# DMASS_DTHE_DMASS_DTHE_DTHE_DTHE_CFG_TRNG76D_WRAP_VBUSP_EIP_76D_8_BCDF_EIP76_4080A000h register map
Vendor: Texas Instruments
Peripheral module from a debugger description file (folder am62L).
Registers are 32-bit, read-only, reset 0x0 unless marked. A register's access mark holds for its fields unless they carry their own. Offsets are as the file gives them; lines under a group give offsets from that group; [hi:lo] are bit positions; {n}, {i} and the like mark numbered series; 'fields as' and 'values as' point back to an identical list; <NAME> marks a mode.

## DMASS_DTHE_DTHE_DTHE_CFG_TRNG76D_WRAP_VBUSP_EIP_76D_8_BCDF_EIP76
0x00 DMASS_DTHE_DTHE_DTHE_CFG_TRNG76D_WRAP_VBUSP_EIP_76D_8_BCDF_EIP76_TRNG_INPUT_0 wo — Input for SP800-90A AES DRBG test
  [31:0] TRNG_INPUT_0 — Write only, least significant word of 128-bit word of test data for [SP 800-90A] AES-256 DRBG testing; may be written when test_ready bit in the TRNG_STATUS register has value 1.
0x00 DMASS_DTHE_DTHE_DTHE_CFG_TRNG76D_WRAP_VBUSP_EIP_76D_8_BCDF_EIP76_TRNG_OUTPUT_0 — Main data output
  [31:0] TRNG_OUTPUT_0 — Read only, least significant word of 128-bit word of random data, only valid when the ready bit in the TRNG_STATUS register has value 1.
0x04 DMASS_DTHE_DTHE_DTHE_CFG_TRNG76D_WRAP_VBUSP_EIP_76D_8_BCDF_EIP76_TRNG_INPUT_1 wo — Input for SP800-90A AES DRBG test
  [31:0] TRNG_INPUT_1 — Write only, second word of 128-bit word of test data for [SP 800-90A] AES-256 DRBG testing; may be written when test_ready bit in the TRNG_STATUS register has value 1.
0x04 DMASS_DTHE_DTHE_DTHE_CFG_TRNG76D_WRAP_VBUSP_EIP_76D_8_BCDF_EIP76_TRNG_OUTPUT_1 — Main data output
  [31:0] TRNG_OUTPUT_1 — Read only, second word of 128-bit word of random data, only valid when the ready bit in the TRNG_STATUS register has value 1.
0x08 DMASS_DTHE_DTHE_DTHE_CFG_TRNG76D_WRAP_VBUSP_EIP_76D_8_BCDF_EIP76_TRNG_INPUT_2 wo — Input for SP800-90A AES DRBG test
  [31:0] TRNG_INPUT_2 — Write only, third word of 128-bit word of test data for [SP 800-90A] AES-256 DRBG testing; may be written when test_ready bit in the TRNG_STATUS register has value 1.
0x08 DMASS_DTHE_DTHE_DTHE_CFG_TRNG76D_WRAP_VBUSP_EIP_76D_8_BCDF_EIP76_TRNG_OUTPUT_2 — Main data output
  [31:0] TRNG_OUTPUT_2 — Read only, third word of 128-bit word of random data, only valid when the ready bit in the TRNG_STATUS register has value 1.
0x0C DMASS_DTHE_DTHE_DTHE_CFG_TRNG76D_WRAP_VBUSP_EIP_76D_8_BCDF_EIP76_TRNG_INPUT_3 wo — Input for SP800-90A AES DRBG test
  [31:0] TRNG_INPUT_3 — Write only, most significant word of 128-bit word of test data for [SP 800-90A] AES-256 DRBG testing; may be written when test_ready bit in the TRNG_STATUS register has value 1.
0x0C DMASS_DTHE_DTHE_DTHE_CFG_TRNG76D_WRAP_VBUSP_EIP_76D_8_BCDF_EIP76_TRNG_OUTPUT_3 — Main data output
  [31:0] TRNG_OUTPUT_3 — Read only, most significant word of 128-bit word of random data, only valid when the ready bit in the TRNG_STATUS register has value 1.
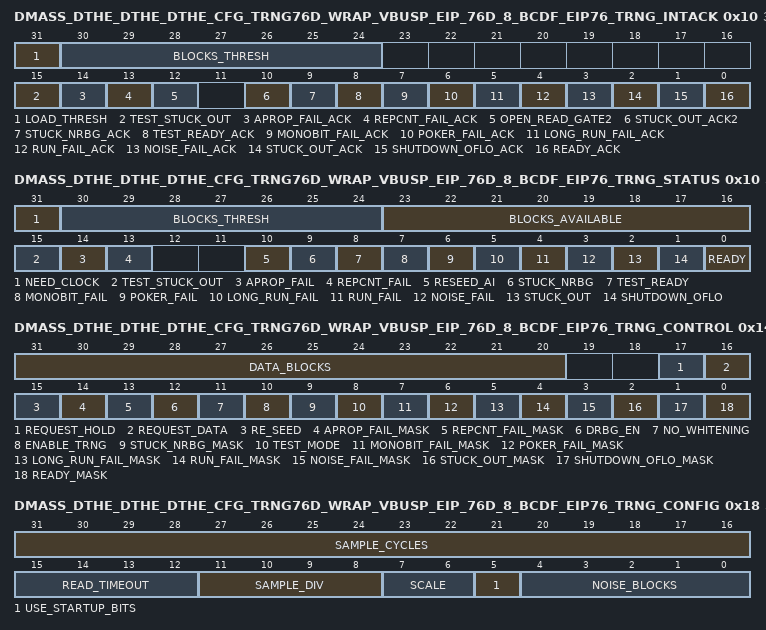
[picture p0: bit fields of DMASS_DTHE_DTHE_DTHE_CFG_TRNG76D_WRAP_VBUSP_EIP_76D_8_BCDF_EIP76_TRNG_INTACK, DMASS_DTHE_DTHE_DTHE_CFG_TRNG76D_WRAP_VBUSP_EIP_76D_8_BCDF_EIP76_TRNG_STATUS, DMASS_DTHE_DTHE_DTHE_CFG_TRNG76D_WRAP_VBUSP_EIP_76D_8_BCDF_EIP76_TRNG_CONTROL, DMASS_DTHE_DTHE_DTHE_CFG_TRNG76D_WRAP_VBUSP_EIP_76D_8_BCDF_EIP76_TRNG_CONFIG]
0x10 DMASS_DTHE_DTHE_DTHE_CFG_TRNG76D_WRAP_VBUSP_EIP_76D_8_BCDF_EIP76_TRNG_INTACK wo — This register is written to acknowledge interrupts indicated in bits [14:0] of the TRNG_STATUS register. Writing a 1 to any of the bits [7:2] here has side effects in resetting various parts of the EIP-76 core logic. This can also be used even if no interrupts are actually active.
  [31] LOAD_THRESH — Write a 1 to load the blocks_thresh field with a new value.
  [30:24] BLOCKS_THRESH — The value written here with load_thresh a 1 determines the filling level of the buffer RAM that must be reached to generate a data available indication the ready bit in the TRNG_STATUS register
  [15] TEST_STUCK_OUT — Write a 1 to enable the stuck_out detection logic testing which prevents updating the data fed to the output buffer module. Can only be modified when also Writing a 1 to stuck_out_ack or stuck_out_ack2 here and can only be set to 1 when test_mode in the TRNG_CONTROL register is a 1.
  [14] APROP_FAIL_ACK — Write a 1 to clear the aprop_fail bit in the TRNG_STATUS register and also clear the aprop_64_fail and aprop_512_fail bits, aprop_64_counter and aprop_512_counter in the TRNG_SPB_TESTS register
  [13] REPCNT_FAIL_ACK — Write a 1 to clear the repcnt_fail bit in the TRNG_STATUS register.
  [12] OPEN_READ_GATE2 — In secure Reading mode, write a 1b here to enable Reading of EIP-76 data from the TRNG_OUTPUT_... registers
  [10] STUCK_OUT_ACK2 — Write a 1 to clear the stuck_out bit in the TRNG_STATUS register.
  [9] STUCK_NRBG_ACK — Write a 1 to clear the stuck_nrbg bit in the TRNG_STATUS register.
  [8] TEST_READY_ACK — Write a 1 to clear the test_ready bit in the TRNG_STATUS register.
  [7] MONOBIT_FAIL_ACK — Write a 1 to clear the monobit_fail bit in the TRNG_STATUS register.
  [6] POKER_FAIL_ACK — Write a 1 to clear the poker_fail bit in the TRNG_STATUS register.
  [5] LONG_RUN_FAIL_ACK — Write a 1 to clear the long_run_fail bit in the TRNG_STATUS register.
  [4] RUN_FAIL_ACK — Write a 1 to clear the run_fail bit in the TRNG_STATUS register.
  [3] NOISE_FAIL_ACK — Write a 1 to clear the noise_fail bit in the TRNG_STATUS register.
  [2] STUCK_OUT_ACK — Write a 1 to clear the stuck_out bit in the TRNG_STATUS register.
  [1] SHUTDOWN_OFLO_ACK — Write a 1 to clear the shutdown_oflo bit in the TRNG_STATUS register.
  [0] READY_ACK — Write a 1 to clear the ready bit in the TRNG_STATUS register.
0x10 DMASS_DTHE_DTHE_DTHE_CFG_TRNG76D_WRAP_VBUSP_EIP_76D_8_BCDF_EIP76_TRNG_INTACK_secure_mode wo — When secure reading mode is enabled, bits [15:0] of this register must be written with zeroes to enable reading of EIP-76 data from the TRNG_OUTPUT_... registers. This also starts the (configurable) timeout counter that will automatically acknowledge the EIP-76 data (and disable reading) if ready_ack is not written with a 1 here within that timeout period.
  [14:0] READY — In secure Reading mode, write an all zeroes value to bits [15:0] to enable Reading of EIP-76 data from the TRNG_OUTPUT_... registers
0x10 DMASS_DTHE_DTHE_DTHE_CFG_TRNG76D_WRAP_VBUSP_EIP_76D_8_BCDF_EIP76_TRNG_STATUS reset 0x400 — The stuck_out and noise_fail bits in this register are considered to signal fatal errors. The shutdown_oflo bit is considered to signal a fatal error when the shutdown_fatal bit in the TRNG_ALARMCNT register is set to 1. If the corresponding ..._mask bits TRNG_CONTROL register are 1 to enable generating an interrupt via the irq output, occurrence of a fatal error disables the TRNG by resetting the enable_trng bit in the TRNG_CONTROL register, zeroizes the random values buffer and forces the ready bit in this register to 0.
  [31] NEED_CLOCK — indicates that the TRNG is busy generating entropy or is in one of its test modes - the module clock may not be turned off. This bit is a direct mirror of the need_clock output signal of the module.
  [30:24] BLOCKS_THRESH — The threshold value for the blocks_available field to indicate ready here. The value is written via bits [30:24] of the TRNG_INTACK register. The number of blocks available in the RAM buffer must be equal to or greater than the value in this field
  [23:16] BLOCKS_AVAILABLE — This field indicates the number of 128 bits blocks of random data that are available in the random data RAM buffer. If this value is non-zero, the output registers will be re-filled from the random data RAM buffer immediately after acknowledging the ready interrupt
  [15] TEST_STUCK_OUT — indication that stuck_out functionality testing is enabled
  [14] APROP_FAIL — 1=the SP 800-90B Adaptive Proportion test logic monitoring the data shifted into the main shift register detected too many 8-bit Noise Source output samples matching the first sample taken in the test window.
  [13] REPCNT_FAIL — 1=the SP 800-90B Repetition Count test logic monitoring the data shifted into the main shift register detected a number of consecutive identical 8-bit Noise Source output samples that matched the programmed cutoff value.
  [10] RESEED_AI — For the EIP-76d configurations with BC_DF functionality, this bit indicates when the TRNG_PS_AI_ registers must be written for an Instantiate or Reseed operation. Writing the highest Byte of the TRNG_PS_AI_11 register then clears this bit. This bit also indicates when the DRBG has finished updating its internal Key and V values after generating random data; no specific action is required at that time.
  [9] STUCK_NRBG — NRBG stuck error; this happens when two identical values were extracted from the main shift register
  [8] TEST_READY — Multi-purpose bit. Please refer to eip76d HW Reference Manual for details
  [7] MONOBIT_FAIL — 1=monobit test logic monitoring data shifted into the main shift register detected an out-of-bounds number of 1s after checking 20,000 bits.
  [6] POKER_FAIL — 1=the AIS-31 poker test logic monitoring data shifted into the main shift register detected an out-of-bounds value in at least one of the 16 poker_count_X counters or an out of bounds sum of squares value after checking 20,000 bits.
  [5] LONG_RUN_FAIL — 1=the AIS-31 run test logic monitoring data shifted into the main shift register detected a sequence of 34 identical bits.
  [4] RUN_FAIL — 1=the AIS-31 run test logic monitoring data shifted into the main shift register detected an out-of-bounds value for at least one of the run_X_count_... counters after checking 20,000 bits.
  [3] NOISE_FAIL — 1=the AIS-31 run test logic monitoring data shifted into the main shift register detected a sequence of 48 identical bits, which is considered a Noise Source failure as proposed in section E.5 of the AIS-31 standard.
  [2] STUCK_OUT — 1=logic around the output data registers4 detected that the EIP-76 generates the same value twice in a row. The word size for this comparison is 128 bits.
  [1] SHUTDOWN_OFLO — 1=the number of FROs shut down after a second error event i.e. the number of 1 bits in the TRNG_ALARMSTOP register has exceeded the threshold set by shutdown_threshold in the TRNG_ALARMCNT register.
  [0] READY — 1=data is available in the TRNG_OUTPUT_0...3 registers. Acknowledging this state by Writing a 1 to bit [0] of the TRNG_INTACK register clears this bit to 0. If a new number is already available in the random data buffer, that number is directly moved into the result register. In this case the ready status bit is asserted again, after at most six module clock cycles.
0x14 DMASS_DTHE_DTHE_DTHE_CFG_TRNG76D_WRAP_VBUSP_EIP_76D_8_BCDF_EIP76_TRNG_CONTROL access per field — This register must be written to start accumulating entropy before random numbers can be generated.
  [31:20] DATA_BLOCKS rw — This field indicates the number of 128 bit data blocks that must be generated by the [SP 800-90A] AES-256 DRBG in a single Generate_function. It is loaded in a write to this register where the request_data bit is 1 (and the re_seed bit is 0) and then counts down to zero by one for each block that is generated.
  [17] REQUEST_HOLD rw — Value 1 in this bit indicates that bits [31:24] of the data_blocks field must be loaded with a separate Byte write
  [16] REQUEST_DATA wo — Write-only, Writing a 1 indicates that the data_blocks field contains the number of 128 bit data blocks that the [SP 800-90A] AES-256 DRBG should generate in a single Generate_function
  [15] RE_SEED rw — Set-only, Writing a 1 starts a Reseed operation. Writing a 0 has no effect.
  [14] APROP_FAIL_MASK rw — 1=allow the corresponding bit in the TRNG_STATUS register to activate the active high irq output
  [13] REPCNT_FAIL_MASK rw — 1=allow the corresponding bit in the TRNG_STATUS register to activate the active high irq output
  [12] DRBG_EN rw — Enable the [SP 800-90A] AES-256 DRBG. If this bit is reset to 0, the DRBG is forced back into the idle state immediately.
  [11] NO_WHITENING rw — The default value of 0 means that toggle-flop whitening of the noise source is enabled. Set this bit to 1 to disable the toggle flip-flop based whitening of the noise source
  [10] ENABLE_TRNG rw — Setting this bit to 1 starts the EIP-76, gathering entropy from the FROs. Resetting this bit to 0 forces all NRBG logic back into the idle state immediately. For the [SP 800-90A] DRBG option, starting the EIP-76 with the drbg_en bit value 1 performs a CTR_DRBG Instantiate operation with Personalization String as written to the TRNG_PS_AI_... registers at that time.
  [9] STUCK_NRBG_MASK rw — 1=allow the corresponding bit in the TRNG_STATUS register to activate the active high irq output
  [8] TEST_MODE rw — Enables access to (amongst others) the TRNG_COUNT and TRNG_RAW_L/H registers (the latter are cleared before enabling access) and keep need_clock output active high for testing purposes. This bit must be set to 1 before various test modes in the TRNG_TEST register can be enabled
  [7] MONOBIT_FAIL_MASK rw — 1=allow the corresponding bit in the TRNG_STATUS register to activate the active high irq output
  [6] POKER_FAIL_MASK rw — 1=allow the corresponding bit in the TRNG_STATUS register to activate the active high irq output
  [5] LONG_RUN_FAIL_MASK rw — 1=allow the corresponding bit in the TRNG_STATUS register to activate the active high irq output
  [4] RUN_FAIL_MASK rw — 1=allow the corresponding bit in the TRNG_STATUS register to activate the active high irq output
  [3] NOISE_FAIL_MASK rw — 1=allow the corresponding bit in the TRNG_STATUS register to activate the active high irq output
  [2] STUCK_OUT_MASK rw — 1=allow the corresponding bit in the TRNG_STATUS register to activate the active high irq output
  [1] SHUTDOWN_OFLO_MASK rw — 1=allow the corresponding bit in the TRNG_STATUS register to activate the active high irq output
  [0] READY_MASK rw — 1=allow the corresponding bit in the TRNG_STATUS register to activate the active high irq output
0x18 DMASS_DTHE_DTHE_DTHE_CFG_TRNG76D_WRAP_VBUSP_EIP_76D_8_BCDF_EIP76_TRNG_CONFIG rw — TRNG Configuration register
  [31:16] SAMPLE_CYCLES — This field, together with the scale field, defines the number of clock cycles before shifting the main shift register and thereby freezing the noise sample. This value must be such that there is at least one bit of entropy (in total) in each 8 bits that are shifted. Please refer to eip76d HW Reference Manual for details
  [15:12] READ_TIMEOUT — This field controls the secure Reading mode. Please refer to eip76d HW Reference Manual for details
  [11:8] SAMPLE_DIV — This field directly controls the number of clk input cycles between samples taken from the FROs. Please refer to eip76d HW Reference Manual for details
  [7:6] SCALE — Set the scale factor for the sample_cycles value. Please refer to eip76d HW Reference Manual for details
  [5] USE_STARTUP_BITS — Do not discard the first 512 bits of raw data. This reduces the start-up time, but may more frequently cause start-up health test failures.
  [4:0] NOISE_BLOCKS — This field sets the number of 512-bit blocks of raw Noise Source output data that must be processed by either the Conditioning Function or the SP 800-90 DRBG BC_DF functionality
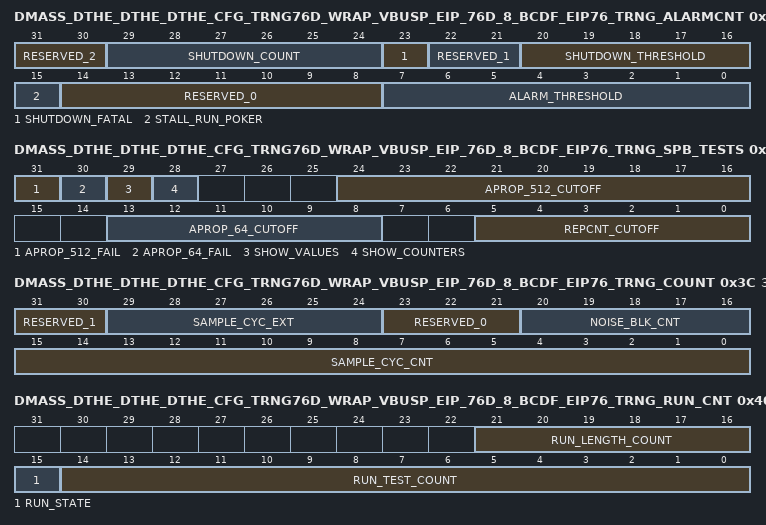
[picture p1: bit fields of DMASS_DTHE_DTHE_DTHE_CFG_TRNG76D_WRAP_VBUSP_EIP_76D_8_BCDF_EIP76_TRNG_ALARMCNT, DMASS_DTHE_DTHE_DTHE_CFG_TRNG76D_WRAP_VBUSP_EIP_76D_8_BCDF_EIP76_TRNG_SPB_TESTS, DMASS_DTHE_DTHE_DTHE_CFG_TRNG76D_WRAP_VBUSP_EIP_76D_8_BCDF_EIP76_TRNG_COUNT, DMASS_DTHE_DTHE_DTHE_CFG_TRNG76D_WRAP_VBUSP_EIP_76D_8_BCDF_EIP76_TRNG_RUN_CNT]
0x1C DMASS_DTHE_DTHE_DTHE_CFG_TRNG76D_WRAP_VBUSP_EIP_76D_8_BCDF_EIP76_TRNG_ALARMCNT access per field reset 0xFF — This register, together with the TRNG_ALARMMASK and TRNG_ALARMSTOP registers, can be used by the Host to determine if the FRO/sample cycle locking is a problem.
  [31:30] RESERVED_2 ro — Bits should be written with a 0 and should be ignored on a read.
  [29:24] SHUTDOWN_COUNT ro — Read-only, indicates the number of 1 bits in the TRNG_ALARMSTOP register. The actual maximum value equals the number of FROs.
  [23] SHUTDOWN_FATAL rw — Threshold setting for generating the shutdown_oflo interrupt, which is activated when the shutdown_count value in this register exceeds the threshold value set here.
  [22:21] RESERVED_1 ro — Bits should be written with a 0 and should be ignored on a read.
  [20:16] SHUTDOWN_THRESHOLD rw — Threshold setting for generating the shutdown_oflo interrupt, which is activated when the shutdown_count value in this register exceeds the threshold value set here.
  [15] STALL_RUN_POKER rw — 1 = Stall the monobit test, run test and poker test circuits when either the monobit_fail, run_fail or poker_fail bits in the TRNG_STATUS register are set to 1 - this allows inspecting the state of the result counters (which would otherwise be reset immediately for the next 20,000 bits block to test)
  [14:8] RESERVED_0 ro — Bits should be written with a 0 and should be ignored on a read.
  [7:0] ALARM_THRESHOLD rw — Alarm detection threshold for the repeating pattern detectors on each FRO. A FRO alarm event is declared when a repeating pattern (of up to four samples length) is detected continuously for the number of samples defined by this field's value. Reset value 255 (decimal) should keep the number of alarm events to a manageable level.
0x20 DMASS_DTHE_DTHE_DTHE_CFG_TRNG76D_WRAP_VBUSP_EIP_76D_8_BCDF_EIP76_TRNG_FROENABLE rw reset 0xFF — This register can be used by the Host to enable and disable FROs individually. Only enabled FROs contribute to entropy generation, but require power to do so. Disabled FROs cannot generate alarm events.
  [7:0] TRNG_FROENABLE — Enable bits for the individual FROs. A 1 in bit [n] enables FRO n. The default state is all ones to enable all FROs after power-up. Note that they are not actually started up before the enable_trng bit in the TRNG_CONTROL register is set to 1. A bit is automatically forced to 0 here (and cannot be written to 1) when the corresponding bit in the TRNG_ALARMSTOP register has value 1.
0x24 DMASS_DTHE_DTHE_DTHE_CFG_TRNG76D_WRAP_VBUSP_EIP_76D_8_BCDF_EIP76_TRNG_FRODETUNE rw — This register can be used by the Host to change the frequencies of individual FROs. This may be used in an effort to reduce the number of alarm events generated by a specific FRO.
  [7:0] TRNG_FRODETUNE — De-tune bits for the individual FROs. A 1 in bit [n] lets FRO n run approximately 5% faster. The value of one of these bits may only be changed while the corresponding FRO is turned off (by temporarily Writing a 0 in the corresponding bit of the TRNG_FROENABLE register).
0x28 DMASS_DTHE_DTHE_DTHE_CFG_TRNG76D_WRAP_VBUSP_EIP_76D_8_BCDF_EIP76_TRNG_ALARMMASK rw — This register can be used by the Host to determine which of the individual FROs generated an alarm event.
  [7:0] TRNG_ALARMMASK — Logging bits for the alarm events of individual FROs. A 1 in bit [n] indicates FRO n experienced an alarm event.
0x2C DMASS_DTHE_DTHE_DTHE_CFG_TRNG76D_WRAP_VBUSP_EIP_76D_8_BCDF_EIP76_TRNG_ALARMSTOP rw — This register can be used by the Host to determine which of the individual FROs generated more than one alarm event in quick succession
  [7:0] TRNG_ALARMSTOP — Logging bits for the alarm events of individual FROs. A 1 in bit [n] indicates FRO n experienced more than one alarm event in quick succession and has been turned off. A 1 in this field forces the corresponding bit in the TRNG_FROENABLE register to 0.
0x30 DMASS_DTHE_DTHE_DTHE_CFG_TRNG76D_WRAP_VBUSP_EIP_76D_8_BCDF_EIP76_TRNG_RAW_L rw — These registers are used to access the main shift register (or its read buffer register) while the test_mode bit in TRNG_CONTROL is set to 1 and either the test_noise or test_known_noise bits in the TRNG_TEST register are set to 1. For security reasons, the main shift register and its buffer register are zeroed when the test_mode bit in TRNG_CONTROL is written from 0 to 1
  [31:0] TRNG_RAW_L — When test_mode in TRNG_CONTROL = 1, test_noise in TRNG_TEST = 1 and test_shiftreg in TRNG_TEST = 0: read-only access to the main shift registers read buffer register bits [31:0]. When test_mode in TRNG_CONTROL = 1, test_noise in TRNG_TEST = 1 and test_shiftreg in TRNG_TEST = 1: read-only access to main shift register bits [31:0]. When test_mode in TRNG_CONTROL = 1 and test_known_noise in TRNG_TEST = 1: write-only access to main shift register bits [31:0].
0x34 DMASS_DTHE_DTHE_DTHE_CFG_TRNG76D_WRAP_VBUSP_EIP_76D_8_BCDF_EIP76_TRNG_RAW_H rw — These registers are used to access the main shift register (or its read buffer register) while the test_mode bit in TRNG_CONTROL is set to 1 and either the test_noise or test_known_noise bits in the TRNG_TEST register are set to 1. For security reasons, the main shift register and its buffer register are zeroed when the test_mode bit in TRNG_CONTROL is written from 0 to 1
  [31:0] TRNG_RAW_H — When test_mode in TRNG_CONTROL = 1, test_noise in TRNG_TEST = 1 and test_shiftreg in TRNG_TEST = 0: read-only access to the main shift registers read buffer register bits [63:32]. When test_mode in TRNG_CONTROL = 1, test_noise in TRNG_TEST = 1 and test_shiftreg in TRNG_TEST = 1: read-only access to main shift register bits [63:32]. When test_mode in TRNG_CONTROL = 1 and test_known_noise in TRNG_TEST = 1: write-only access to main shift register bits [63:32].
0x38 DMASS_DTHE_DTHE_DTHE_CFG_TRNG76D_WRAP_VBUSP_EIP_76D_8_BCDF_EIP76_TRNG_SPB_TESTS rw reset 0x145381F — Allows setting the cutoff values for the Repetition Count and Adaptive Proportion tests required by that standard. The Adaptive Proportion test is run with window sizes of 512 and 64 Noise Source samples in parallel. All these tests use 8-bit Noise Source samples. In test_spb mode, this register allows monitoring the counters and compare values.
  [31] APROP_512_FAIL — Bit indicating that the aprop_512_counter was equal to the aprop_512_cutoff setting. The state of this bit is OR-ed with the aprop_64_fail bit into the aprop_fail bit in the TRNG_STATUS register and cleared to 0 when Writing a 1 to the aprop_fail_ack bit of the TRNG_INTACK register. While normal
  [30] APROP_64_FAIL — Bit indicating that the aprop_64_counter was equal to the aprop_64_cutoff setting. The state of this bit is OR-ed with the aprop_512_fail bit into the aprop_fail bit in the TRNG_STATUS register and cleared to 0 when Writing a 1 to the aprop_fail_ack bit of the TRNG_INTACK register. While normally read-only, this bit can be written when test_spb in TRNG_TEST is 1.
  [29] SHOW_VALUES — Bit controlling what is actually accessible in this register; can only be set to 1 when test_spb in TRNG_TEST is 1. When Writing this bit to a different value, all other bits in this register are preserved. When Writing both show_counters and show_values with a 1 while test_spb in TRNG_TEST is 1, all bits in this register are preserved but the 12-bit internal cycle counter for the Adaptive Proportion tests is reset to its initial state.
  [28] SHOW_COUNTERS — Bit controlling what is actually accessible in this register; can only be set to 1 when show_values is written 0 and test_spb in TRNG_TEST is 1. When Writing this bit to a different value all other bits in this register are preserved. When Writing both show_counters and show_values with a 1 while test_spb in TRNG_TEST is 1, all bits in this register are preserved but the 12-bit internal cycle counter for the Adaptive Proportion tests is reset to its initial state.
  [24:16] APROP_512_CUTOFF — Adaptive Proportion test cutoff value for the 512 Noise Source samples window size test, accessible when show_counters and show_values are both 0. The reset value of 325 corresponds to the cutoff value for a false positive rate of 2-30 and 1 bit of entropy per 8-bit Noise Source sample. This field can only be modified while enable_trng in TRNG_CONTROL is 0 or test_spb in TRNG_TEST is 1. Value 0 in this field disables the Adaptive Proportion test with 512 Noise Source samples window size.
  [13:8] APROP_64_CUTOFF — Adaptive Proportion test cutoff value for the 64 Noise Source samples window size test, accessible when show_counters and show_values are both 0. The reset value of 56 corresponds to the cutoff value for a false positive rate of 2-30 and 1 bit of entropy per 8-bit Noise Source sample. This field can only be modified while enable_trng in TRNG_CONTROL is 0 or test_spb in TRNG_TEST is 1. Value 0 in this field disables the Adaptive Proportion test with 64 Noise Source samples window size.
  [5:0] REPCNT_CUTOFF — Repetition Count test cutoff value, accessible when show_counters and show_values are both 0. The reset value of 31 corresponds to the cutoff value for a false positive rate of 2-30 and 1 bit of entropy per 8-bit Noise Source sample. This field can only be modified while enable_trng in TRNG_CONTROL is 0 or test_spb in TRNG_TEST is 1. Value 0 in this field disables the Repetition Count test.
0x3C DMASS_DTHE_DTHE_DTHE_CFG_TRNG76D_WRAP_VBUSP_EIP_76D_8_BCDF_EIP76_TRNG_COUNT — This register is used to access the main control timing counters while the test_mode bit in TRNG_CONTROL is set to 1.
  [31:30] RESERVED_1 — Bits should be written with a 0 and should be ignored on a read.
  [29:24] SAMPLE_CYC_EXT — Extension bits for the sample cycle counter, used when the scale field in the TRNG_CONFIG register is non-zero. This counter can only be accessed when the test_mode bit in TRNG_CONTROL is set to 1
  [23:21] RESERVED_0 — Bits should be written with a 0 and should be ignored on a read.
  [20:16] NOISE_BLK_CNT — Noise blocks counter used to control the number of 512-bits noise blocks to be handled by the BC_DF functionality in the SP 800-90A DRBG (depending on configuration). The start value of this counter is 1, which is also the value to which it is reset when it reaches the value of the noise_blocks field in the TRNG_CONFIG register. This counter can only be accessed when test_mode bit in TRNG_CONTROL is set to 1, restricted to read-only accesses when the test_noise bit in the TRNG_TEST register is 1
  [15:0] SAMPLE_CYC_CNT — Lowest 16 bits of the sample cycle counter used to control the number of (XOR-ed) FRO samples that are XOR-ed together into a single noise bit. The start value of this counter is 1, which is also the value to which it is reset when it reaches the value defined by the sample_cycles and scale fields in the TRNG_CONFIG register. This counter can only be accessed when the test_mode bit in TRNG_CONTROL is set to 1.
{0x40+4i} DMASS_DTHE_DTHE_DTHE_CFG_TRNG76D_WRAP_VBUSP_EIP_76D_8_BCDF_EIP76_TRNG_PS_AI_{i} wo (i=0..11) — These registers are used to hold Personalization Strings, Nonces and Additional Inputs for the SP 800-90A DRBG.
  [31:0] VECTOR — Personalization string or Additional Input for reseed and generate function of the DRBG, or in test mode this register is the DRBG AES256 test key TRNG_KEY_{i}
0x40 DMASS_DTHE_DTHE_DTHE_CFG_TRNG76D_WRAP_VBUSP_EIP_76D_8_BCDF_EIP76_TRNG_RUN_CNT — These registers are used to access the 10 counters used to perform a run test and long run test as specified by the [AIS-31] standard (tests T3 and T4).
  [21:16] RUN_LENGTH_COUNT — Counter for the current run of consecutive 0/1 bits; cannot increment past its maximum value of 63.
  [15] RUN_STATE — The state of bits in the current run.
  [14:0] RUN_TEST_COUNT — Block length counter for the run and poker tests - counts up for 20,000 tested bits and then controls testing of the run_X_count_... and poker_count_X counters to contain expected values, after which they and this counter are reset for the next block.
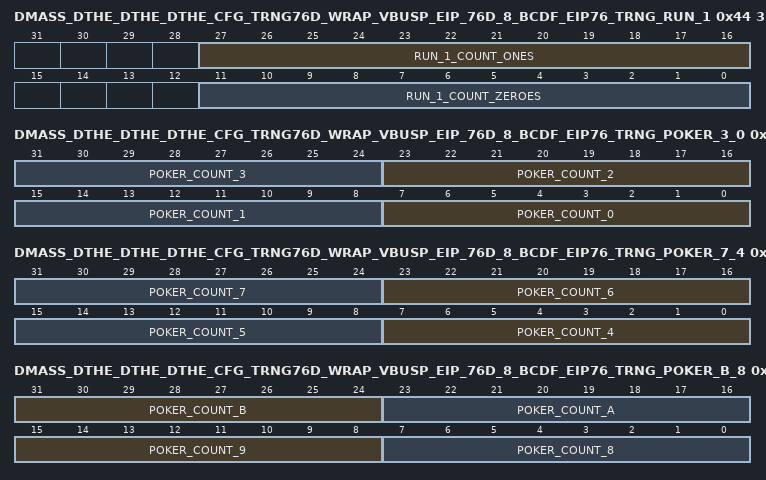
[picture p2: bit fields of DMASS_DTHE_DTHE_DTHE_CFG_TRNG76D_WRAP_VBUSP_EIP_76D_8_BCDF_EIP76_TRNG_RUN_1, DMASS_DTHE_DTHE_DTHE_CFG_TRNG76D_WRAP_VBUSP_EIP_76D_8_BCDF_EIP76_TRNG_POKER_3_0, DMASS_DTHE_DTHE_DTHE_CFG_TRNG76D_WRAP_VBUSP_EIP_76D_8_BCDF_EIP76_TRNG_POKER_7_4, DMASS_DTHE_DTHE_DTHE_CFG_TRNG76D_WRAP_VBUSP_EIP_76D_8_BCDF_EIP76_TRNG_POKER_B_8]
{0x40+4i} DMASS_DTHE_DTHE_DTHE_CFG_TRNG76D_WRAP_VBUSP_EIP_76D_8_BCDF_EIP76_TRNG_RUN_{i} (i=1..6) — All run test state and result registers are all read-only - writing them accesses TRNG_KEY and TRNG_PS_AI registers mapped at the same address
  [27:16] RUN_{i}_COUNT_ONES — Counter for single bit runs of value one bits
  [11:0] RUN_{i}_COUNT_ZEROES — Counter for single bit runs of value zero bits
0x5C DMASS_DTHE_DTHE_DTHE_CFG_TRNG76D_WRAP_VBUSP_EIP_76D_8_BCDF_EIP76_TRNG_MONOBITCNT reset 0x2710 — This register accesses the counter used perform a monobit test as specified by the [AIS-31] standard (test T1). This test is performed on blocks of 20,000 bits
  [15:0] MONOBIT_COUNT — Up/down counter monitoring 1 and 0 bits. After 20,000 bits, this counter should have a value in the range 9310 - 10690 (inclusive) to pass the monobit test. This counter is protected against overflow and underflow.
0x60 DMASS_DTHE_DTHE_DTHE_CFG_TRNG76D_WRAP_VBUSP_EIP_76D_8_BCDF_EIP76_TRNG_POKER_3_0 reset 0xFFFFFFFF — Poker test counts values 0-3
  [8n+7:8n] POKER_COUNT_{n} (n=0..3) — poker test counter
0x64 DMASS_DTHE_DTHE_DTHE_CFG_TRNG76D_WRAP_VBUSP_EIP_76D_8_BCDF_EIP76_TRNG_POKER_7_4 reset 0xFFFFFFFF — Poker test counts values 4-7
  [8n-25:8n-32] POKER_COUNT_{n} (n=4..7) — poker test counter
0x68 DMASS_DTHE_DTHE_DTHE_CFG_TRNG76D_WRAP_VBUSP_EIP_76D_8_BCDF_EIP76_TRNG_POKER_B_8 reset 0xFFFFFFFF — Poker test counts values 8-B
  [31:24] POKER_COUNT_B — poker test counter
  [23:16] POKER_COUNT_A — poker test counter
  [15:8] POKER_COUNT_9 — poker test counter
  [7:0] POKER_COUNT_8 — poker test counter
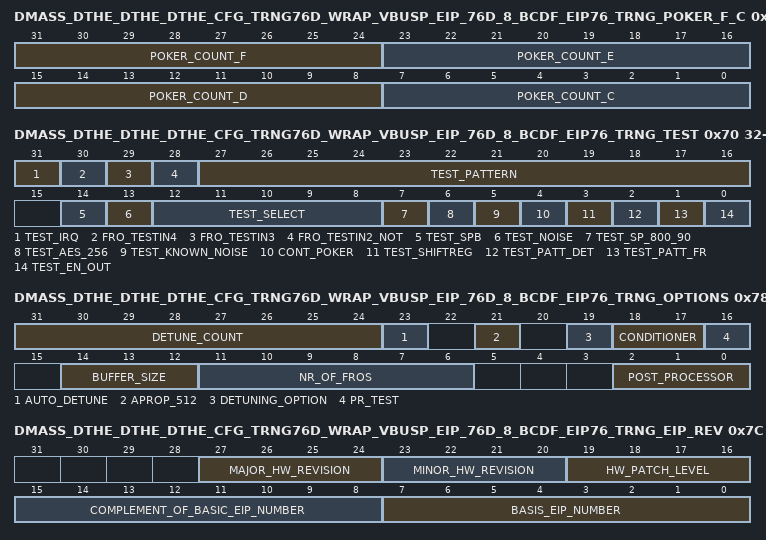
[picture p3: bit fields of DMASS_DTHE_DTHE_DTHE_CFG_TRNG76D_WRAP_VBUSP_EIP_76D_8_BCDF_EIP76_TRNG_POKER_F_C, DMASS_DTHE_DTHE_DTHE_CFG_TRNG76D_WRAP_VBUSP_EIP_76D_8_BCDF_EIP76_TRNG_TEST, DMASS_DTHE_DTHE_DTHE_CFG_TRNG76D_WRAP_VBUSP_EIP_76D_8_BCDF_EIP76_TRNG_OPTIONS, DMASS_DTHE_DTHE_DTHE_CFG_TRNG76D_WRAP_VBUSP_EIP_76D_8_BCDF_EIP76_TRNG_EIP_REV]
0x6C DMASS_DTHE_DTHE_DTHE_CFG_TRNG76D_WRAP_VBUSP_EIP_76D_8_BCDF_EIP76_TRNG_POKER_F_C reset 0xFFFFFFFF — Poker test counts values C-F
  [31:24] POKER_COUNT_F — poker test counter
  [23:16] POKER_COUNT_E — poker test counter
  [15:8] POKER_COUNT_D — poker test counter
  [7:0] POKER_COUNT_C — poker test counter
0x70 DMASS_DTHE_DTHE_DTHE_CFG_TRNG76D_WRAP_VBUSP_EIP_76D_8_BCDF_EIP76_TRNG_TEST rw — This register can be used by the Host to perform a number of tests on the TRNG logic.
  [31] TEST_IRQ — force irq output high for interrupt signal connectivity testing.
  [30] FRO_TESTIN4 — Control bit driving the fro_testin4 output of the TRNG module, which connects to all the select inputs on the test multiplexers in the FROs
  [29] FRO_TESTIN3 — Control bit driving the fro_testin3 output of the TRNG module, which connects to all the OR inputs on the AND-OR gates in the FRO chains. The actual output has the state of this bit, so a 0 does not disturb the operation of the FROs. The actual output has the state of this bit, so a 0 selects the output of the delay control multiplexers. A 1 here also forces the fro_enable[n] output (with n equal to the value of the test_select field here) to 1 - this allows testing the signal path through the AND-OR-INVERT gate in the FROs.
  [28] FRO_TESTIN2_NOT — Control bit driving the fro_testin2 output of the TRNG module, which connects to all the AND inputs on the AND-OR gates in the FRO chains (see Figure 3). The actual output is the complement of this bit, so a 0 does not disturb the operation of the FROs.
  [27:16] TEST_PATTERN — Repeating sequence of bits to be fed into the selected FRO delay chain and/or the selected FRO error detection circuit
  [14] TEST_SPB — Enable testing of the [SP 800-90B] Repetition Count and Adaptive Proportion tests by allowing the show_counters and show_values bits in the TRNG_SPB_TESTS register to be set non-zero. To perform Known Answer Tests on those functions, the test_known_noise bit in this register must be set to 1 too.
  [13] TEST_NOISE — Enable Noise Source testing, making 64 bit blocks of Noise Source output available in the TRNG_RAW_... registers. When test_shiftreg is 0, these must be acknowledged by Writing a 1 to the test_ready_ack bit in the TRNG_ACK register.
  [12:8] TEST_SELECT — Number of the FRO to be tested
  [7] TEST_SP_800_90 — Provide direct access to the [SP 800-90A] DRBG (EIP-76d) for NIST compliant known-answer tests (DRBG state is lost during testing).
  [6] TEST_AES_256 — Dual purpose bit that is only present when an [SP 800-90A] DRBG is available (EIP-76d) and can only be set to 1 when the drbg_en bit in the TRNG_CONTROL register is 1 and the test_known_noise bit in this register is 0.
  [5] TEST_KNOWN_NOISE — Allow Writing of known test data into the main shift register (Writing input data in chunks of 64 bits to the TRNG_RAW_L and TRNG_RAW_H registers) and allow Writing of the noise_blocks, sample_interval and sample_cycles fields in the TRNG_CONFIG register. This allows testing the [SP 800-90B] Repetition Count and Adaptive Proportion tests, the (optional) [AIS-31] run, poker and monobit tests, and the [SP 800-90A] BC_DF function
  [4] CONT_POKER — Keep monobit test and poker test running continuously by not resetting the monobit_count and poker_count_X counters at the end of each 20,000 bits test block.
  [3] TEST_SHIFTREG — Read directly from the main shift register when test_noise is set to 1, 0 = read from the shift register buffer (using the test_ready bit in the TRNG_STATUS register to indicate that a new batch of 64 bits can be read).
  [2] TEST_PATT_DET — Repeatedly feed test_pattern into the error detection circuit of the FRO selected by the test_select field.
  [1] TEST_PATT_FR — Repeatedly feed test_pattern into the delay chain of the FRO selected by the test_select field by forcing the corresponding fro_enable output low and forcing the corresponding fro_testin output to the state of bit [16] of this register.
  [0] TEST_EN_OUT — Enable the tst_fro_clk_out output, connecting to the FRO selected by the test_select field.
0x74 DMASS_DTHE_DTHE_DTHE_CFG_TRNG76D_WRAP_VBUSP_EIP_76D_8_BCDF_EIP76_TRNG_BLOCKCNT rw — TRNG Block Count Register.
  [31:4] BLOCK_COUNT — Counter for the number of 128-bit blocks generated by the DRBG. It is forced back to zero when the DRBG is disabled and cleared to zero when an internal Reseed operation has finished. This register can be used by driver software to determine when to Reseed the DRBG.
0x78 DMASS_DTHE_DTHE_DTHE_CFG_TRNG76D_WRAP_VBUSP_EIP_76D_8_BCDF_EIP76_TRNG_OPTIONS access per field reset 0x292205 — This register provides the Host with a means to determine the hardware configuration implemented in this TRNG Engine. It is focused on options that have an effect on software interacting with the module.
  [31:24] DETUNE_COUNT rw — Indicates the number of detune events that occurred on the enabled FROs. The counter is incremented by one on each detune event up to a value 255. The counter will remain at 255 when more detune events occur. The counter can be cleared by Writing value 0xFF to this field (any other value has no effect)
  [23] AUTO_DETUNE rw — When written with 1, automatic detuning is enabled. For the basic functionality, the detuning is done when shutdown_count exceeds shutdown_threshold. At that point FROs that have a 1 in the TRNG_ALARMSTOP register are re-enabled in the TRNG_FROENABLE register, have their detune bit flipped in the TRNG_FRODETUNE register and their bits cleared in the TRNG_ALARMMASK and TRNG_ALARMSTOP registers.
  [21] APROP_512 ro — The Adaptive Proportion test works with a window size of 512 bits, as specified in [SP 800-90B].
  [19] DETUNING_OPTION ro — detuning functionality is present
  [18:17] CONDITIONER ro — a BC_DF Conditioning Function is present when an AES DRBG is present as well.
  [16] PR_TEST ro — Indicates that Monobit, poker and run test circuits are available.
  [14:12] BUFFER_SIZE ro — value 2 indicates a 4 blocks/512 bits/64 Byte/16 word buffer
  [11:6] NR_OF_FROS ro — Number of FROs implemented in this TRNG
  [2:0] POST_PROCESSOR ro — 5: an SP 800-90A AES-256 DRBG is present
0x7C DMASS_DTHE_DTHE_DTHE_CFG_TRNG76D_WRAP_VBUSP_EIP_76D_8_BCDF_EIP76_TRNG_EIP_REV reset 0x244B34C — TRNG HW Revision Register
  [27:24] MAJOR_HW_REVISION, [23:20] MINOR_HW_REVISION, [19:16] HW_PATCH_LEVEL, [15:8] COMPLEMENT_OF_BASIC_EIP_NUMBER, [7:0] BASIS_EIP_NUMBER
